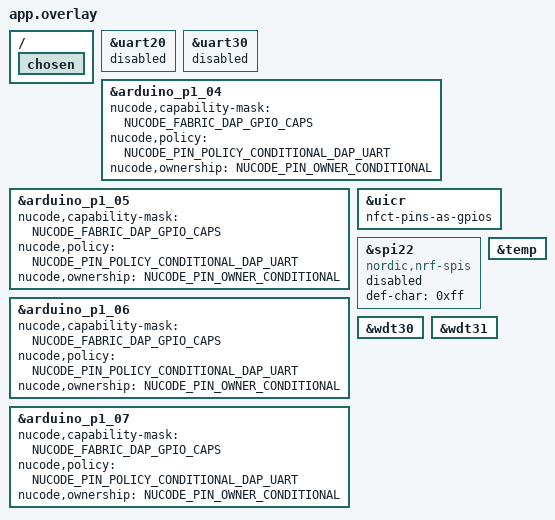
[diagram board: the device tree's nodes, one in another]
/**
 * @file app.overlay
 * @brief 직접 Peripheral Fabric이 serial·GPIO 자원을 소유하도록 구성합니다.
 *
 * SPDX-License-Identifier: MIT
 */

#include <nucode/nu54dk-arduino-connectors.dtsi>
#include <nucode/nu54dk-arduino-pins.dtsi>
#include <nucode/nu54dk-arduino-runtime.dtsi>

/ {
    chosen {
        /delete-property/ zephyr,console;
        /delete-property/ zephyr,shell-uart;
        /delete-property/ zephyr,uart-mcumgr;
        /delete-property/ zephyr,bt-mon-uart;
        /delete-property/ zephyr,bt-c2h-uart;
    };
};

&uart20 {
    status = "disabled";
};

&uart30 {
    status = "disabled";
};

/** @brief DAP UART 분리 profile에서 P1.4~P1.7을 조건부 Fabric 핀으로 전환합니다. */
#define NUCODE_FABRIC_DAP_GPIO_CAPS                                                                  \
    (NUCODE_PIN_CAP_INPUT | NUCODE_PIN_CAP_OUTPUT | NUCODE_PIN_CAP_ANALOG |                         \
     NUCODE_PIN_CAP_OPEN_DRAIN | NUCODE_PIN_CAP_INTERRUPT)

&arduino_p1_04 {
    nucode,capability-mask = <NUCODE_FABRIC_DAP_GPIO_CAPS>;
    nucode,policy = <NUCODE_PIN_POLICY_CONDITIONAL_DAP_UART>;
    nucode,ownership = <NUCODE_PIN_OWNER_CONDITIONAL>;
};

&arduino_p1_05 {
    nucode,capability-mask = <NUCODE_FABRIC_DAP_GPIO_CAPS>;
    nucode,policy = <NUCODE_PIN_POLICY_CONDITIONAL_DAP_UART>;
    nucode,ownership = <NUCODE_PIN_OWNER_CONDITIONAL>;
};

&arduino_p1_06 {
    nucode,capability-mask = <NUCODE_FABRIC_DAP_GPIO_CAPS>;
    nucode,policy = <NUCODE_PIN_POLICY_CONDITIONAL_DAP_UART>;
    nucode,ownership = <NUCODE_PIN_OWNER_CONDITIONAL>;
};

&arduino_p1_07 {
    nucode,capability-mask = <NUCODE_FABRIC_DAP_GPIO_CAPS>;
    nucode,policy = <NUCODE_PIN_POLICY_CONDITIONAL_DAP_UART>;
    nucode,ownership = <NUCODE_PIN_OWNER_CONDITIONAL>;
};

#undef NUCODE_FABRIC_DAP_GPIO_CAPS

/** @brief P1.2/P1.3을 승인된 TWI 경로로 사용할 수 있게 합니다. */
&uicr {
    nfct-pins-as-gpios;
};

/** @brief SPIS22 직접 nrfx 경로가 Zephyr driver 없이 node identity를 사용합니다. */
&spi22 {
    compatible = "nordic,nrf-spis";
    /delete-property/ rx-delay-supported;
    /delete-property/ rx-delay;
    def-char = <0xff>;
    status = "disabled";
};

/** @brief System Fabric이 사용하는 온칩 TEMP와 두 watchdog driver를 활성화합니다. */
&temp {
    status = "okay";
};

&wdt30 {
    status = "okay";
};

&wdt31 {
    status = "okay";
};
